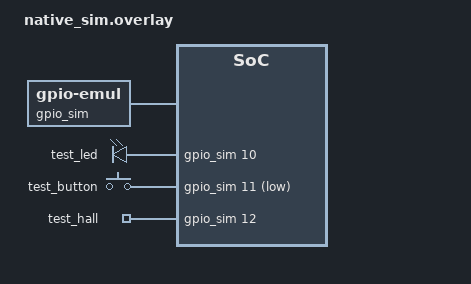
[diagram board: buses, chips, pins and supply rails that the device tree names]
/ {
    aliases {
        led0 = &test_led;
        sw0 = &test_button;
        hal0 = &test_hall;
    };

    /* This node replaces the nRF5340 GPIO peripheral for simulations */
    gpio_sim: gpio_sim {
        compatible = "zephyr,gpio-emul";
        gpio-controller;
        #gpio-cells = <2>;
        status = "okay";
    };

    leds {
        compatible = "gpio-leds";
        test_led: led_0 {
            gpios = <&gpio_sim 10 GPIO_ACTIVE_HIGH>;
        };
    };

    buttons {
        compatible = "gpio-keys";
        test_button: btn_0 {
            gpios = <&gpio_sim 11 (GPIO_PULL_UP | GPIO_ACTIVE_LOW)>;
        };
        test_hall: hall_0 {
            gpios = <&gpio_sim 12 GPIO_ACTIVE_HIGH>;
        };
    };
};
